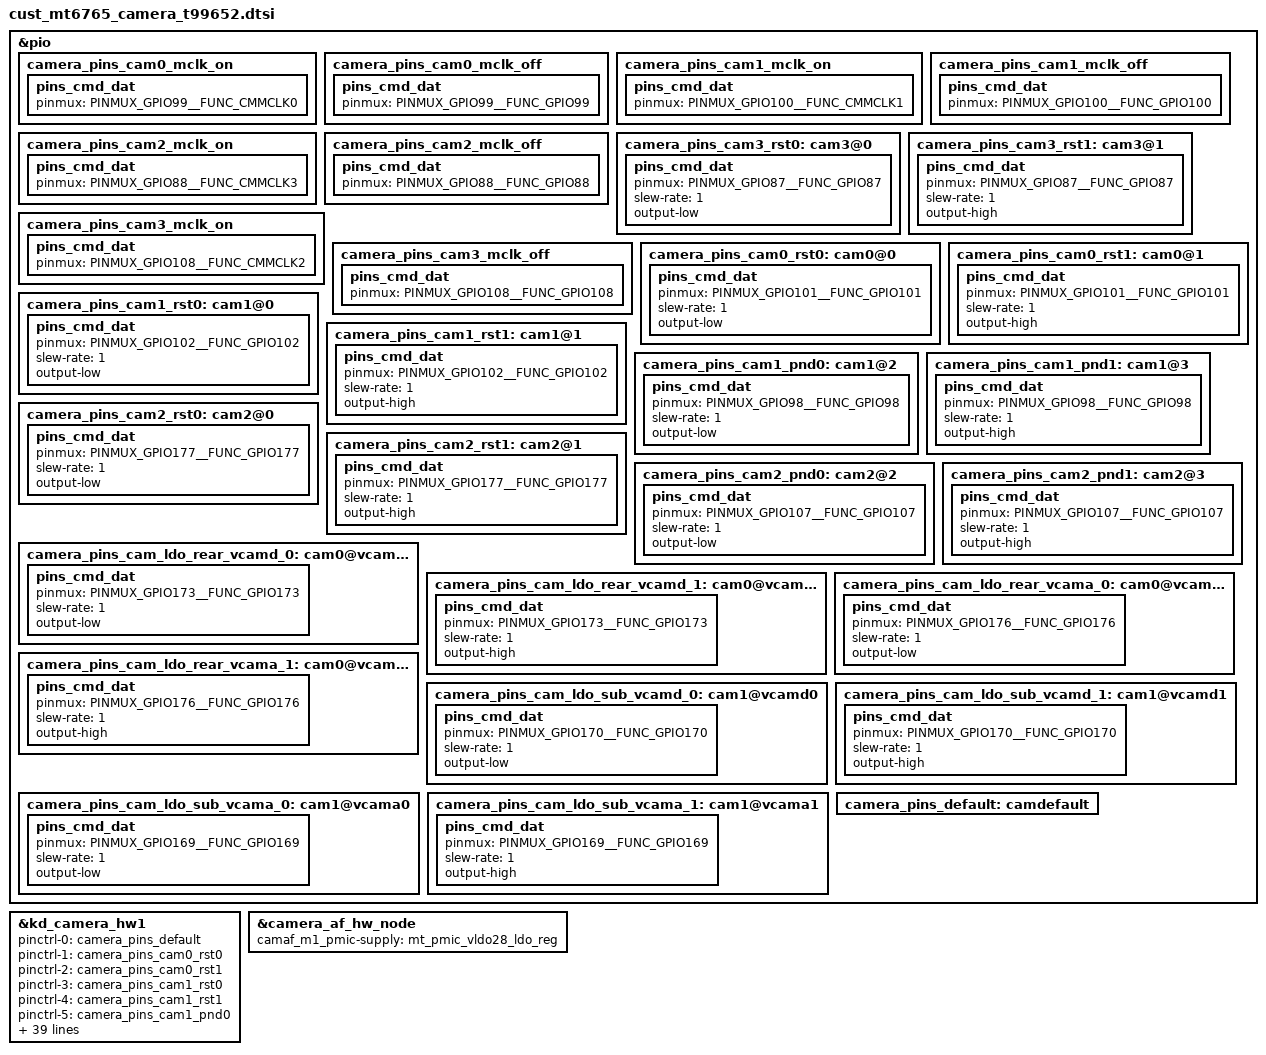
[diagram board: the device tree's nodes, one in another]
// SPDX-License-Identifier: GPL-2.0+
/*
 * Copyright (c) 2019 MediaTek Inc.
 *
 */

/* CAMERA GPIO standardization */
&pio {
	camera_pins_cam0_mclk_on: camera_pins_cam0_mclk_on {
		pins_cmd_dat {
			pinmux = <PINMUX_GPIO99__FUNC_CMMCLK0>;
		};
	};
	camera_pins_cam0_mclk_off: camera_pins_cam0_mclk_off {
		pins_cmd_dat {
			pinmux = <PINMUX_GPIO99__FUNC_GPIO99>;
		};
	};
	camera_pins_cam1_mclk_on: camera_pins_cam1_mclk_on {
		pins_cmd_dat {
			pinmux = <PINMUX_GPIO100__FUNC_CMMCLK1>;
		};
	};
	camera_pins_cam1_mclk_off: camera_pins_cam1_mclk_off {
		pins_cmd_dat {
			pinmux = <PINMUX_GPIO100__FUNC_GPIO100>;
		};
	};
	camera_pins_cam2_mclk_on: camera_pins_cam2_mclk_on {
		pins_cmd_dat {
			pinmux = <PINMUX_GPIO88__FUNC_CMMCLK3>;
		};
	};
	camera_pins_cam2_mclk_off: camera_pins_cam2_mclk_off {
		pins_cmd_dat {
			pinmux = <PINMUX_GPIO88__FUNC_GPIO88>;
		};
	};
    /*+bug584789,liuxingyu.wt,MODIFY,2020/10/13,rogue hi556 gc02m1 sensor bringup*/
	camera_pins_cam3_rst0: cam3@0 {
		pins_cmd_dat {
			pinmux = <PINMUX_GPIO87__FUNC_GPIO87>;
			slew-rate = <1>;
			output-low;
		};
	};
	camera_pins_cam3_rst1: cam3@1 {
		pins_cmd_dat {
			pinmux = <PINMUX_GPIO87__FUNC_GPIO87>;
			slew-rate = <1>;
			output-high;
		};
	};
/*+bug595172,zhanghengyuan.wt,DELETE,2020/10/19,camera gpio160 customization*/
/*
	camera_pins_cam3_pnd0: cam3@2 {
		pins_cmd_dat {
			pinmux = <PINMUX_GPIO160__FUNC_GPIO160>;
			slew-rate = <1>;
			output-low;
		};
	};
	camera_pins_cam3_pnd1: cam3@3 {
		pins_cmd_dat {
			pinmux = <PINMUX_GPIO160__FUNC_GPIO160>;
			slew-rate = <1>;
			output-high;
		};
	};
*/
/*-bug595172,zhanghengyuan.wt,DELETE,2020/10/19,camera gpio160 customization*/
	camera_pins_cam3_mclk_on: camera_pins_cam3_mclk_on {
		pins_cmd_dat {
			pinmux = <PINMUX_GPIO108__FUNC_CMMCLK2>;
		};
	};
	camera_pins_cam3_mclk_off: camera_pins_cam3_mclk_off {
		pins_cmd_dat {
			pinmux = <PINMUX_GPIO108__FUNC_GPIO108>;
		};
	};
    /*-bug584789,liuxingyu.wt,MODIFY,2020/10/13,rogue hi556 gc02m1 sensor bringup*/
	camera_pins_cam0_rst0: cam0@0 {
		pins_cmd_dat {
			pinmux = <PINMUX_GPIO101__FUNC_GPIO101>;
			slew-rate = <1>;
			output-low;
		};
	};
	camera_pins_cam0_rst1: cam0@1 {
		pins_cmd_dat {
			pinmux = <PINMUX_GPIO101__FUNC_GPIO101>;
			slew-rate = <1>;
			output-high;
		};
	};
//+bug584789,chenbocheng.wt,REMOVE,2020/10/31,the gpio97 pin is the charge enalbe pin
/*
	camera_pins_cam0_pnd0: cam0@2 {
		pins_cmd_dat {
			pinmux = <PINMUX_GPIO97__FUNC_GPIO97>;
			slew-rate = <1>;
			output-low;
		};
	};
	camera_pins_cam0_pnd1: cam0@3 {
		pins_cmd_dat {
			pinmux = <PINMUX_GPIO97__FUNC_GPIO97>;
			slew-rate = <1>;
			output-high;
		};
	};
*/
//-bug584789,chenbocheng.wt,REMOVE,2020/10/31,the gpio97 pin is the charge enalbe pin
	camera_pins_cam1_rst0: cam1@0 {
		pins_cmd_dat {
			pinmux = <PINMUX_GPIO102__FUNC_GPIO102>;
			slew-rate = <1>;
			output-low;
		};
	};
	camera_pins_cam1_rst1: cam1@1 {
		pins_cmd_dat {
			pinmux = <PINMUX_GPIO102__FUNC_GPIO102>;
			slew-rate = <1>;
			output-high;
		};
	};
	camera_pins_cam1_pnd0: cam1@2 {
		pins_cmd_dat {
			pinmux = <PINMUX_GPIO98__FUNC_GPIO98>;
			slew-rate = <1>;
			output-low;
		};
	};
	camera_pins_cam1_pnd1: cam1@3 {
		pins_cmd_dat {
			pinmux = <PINMUX_GPIO98__FUNC_GPIO98>;
			slew-rate = <1>;
			output-high;
		};
	};
	camera_pins_cam2_rst0: cam2@0 {
		pins_cmd_dat {
			pinmux = <PINMUX_GPIO177__FUNC_GPIO177>;
			slew-rate = <1>;
			output-low;
		};
	};
	camera_pins_cam2_rst1: cam2@1 {
		pins_cmd_dat {
			pinmux = <PINMUX_GPIO177__FUNC_GPIO177>;
			slew-rate = <1>;
			output-high;
		};
	};
/*bug584789,zhanghengyuan.wt,MODIFY,2020/10/14,rogue gc02m1b sensor bringup*/
	camera_pins_cam2_pnd0: cam2@2 {
		pins_cmd_dat {
			pinmux = <PINMUX_GPIO107__FUNC_GPIO107>;
			slew-rate = <1>;
			output-low;
		};
	};
	camera_pins_cam2_pnd1: cam2@3 {
		pins_cmd_dat {
			pinmux = <PINMUX_GPIO107__FUNC_GPIO107>;
			slew-rate = <1>;
			output-high;
		};
	};
/*bug584789,zhanghengyuan.wt,MODIFY,2020/10/14,rogue gc02m1b sensor bringup*/
        /*+bug584789,zhouyikuan.wt,MODIFY,2020/10/12,rogue_dongci_s5k3l6 sensor bringup*/
	camera_pins_cam_ldo_rear_vcamd_0: cam0@vcamd0 {
		pins_cmd_dat {
			pinmux = <PINMUX_GPIO173__FUNC_GPIO173>;
			slew-rate = <1>;
			output-low;
		};
	};
	camera_pins_cam_ldo_rear_vcamd_1: cam0@vcamd1 {
		pins_cmd_dat {
			pinmux = <PINMUX_GPIO173__FUNC_GPIO173>;
			slew-rate = <1>;
			output-high;
		};
	};
    camera_pins_cam_ldo_rear_vcama_0: cam0@vcama0 {
            pins_cmd_dat {
                    pinmux = <PINMUX_GPIO176__FUNC_GPIO176>;
                    slew-rate = <1>;
                    output-low;
            };
    };
    camera_pins_cam_ldo_rear_vcama_1: cam0@vcama1 {
            pins_cmd_dat {
                    pinmux = <PINMUX_GPIO176__FUNC_GPIO176>;
                    slew-rate = <1>;
                    output-high;
            };
    };
    /*-bug584789,zhouyikuan.wt,MODIFY,2020/10/12,rogue_dongci_s5k3l6 sensor bringup*/
	camera_pins_cam_ldo_sub_vcamd_0: cam1@vcamd0 {
		pins_cmd_dat {
			pinmux = <PINMUX_GPIO170__FUNC_GPIO170>;
			slew-rate = <1>;
			output-low;
		};
	};
	camera_pins_cam_ldo_sub_vcamd_1: cam1@vcamd1 {
		pins_cmd_dat {
			pinmux = <PINMUX_GPIO170__FUNC_GPIO170>;
			slew-rate = <1>;
			output-high;
		};
	};
	camera_pins_cam_ldo_sub_vcama_0: cam1@vcama0 {
		pins_cmd_dat {
			pinmux = <PINMUX_GPIO169__FUNC_GPIO169>;
			slew-rate = <1>;
			output-low;
		};
	};
	camera_pins_cam_ldo_sub_vcama_1: cam1@vcama1 {
		pins_cmd_dat {
			pinmux = <PINMUX_GPIO169__FUNC_GPIO169>;
			slew-rate = <1>;
			output-high;
		};
	};
	camera_pins_default: camdefault {
	};

};

&kd_camera_hw1 {
	pinctrl-names = "default",
			"cam0_rst0",
			"cam0_rst1",
			//"cam0_pnd0",
			//"cam0_pnd1",
			"cam1_rst0",
			"cam1_rst1",
			"cam1_pnd0",
			"cam1_pnd1",
			"cam2_rst0",
			"cam2_rst1",
			"cam2_pnd0",
			"cam2_pnd1",
			"cam0_vcamd_on",
			"cam0_vcamd_off",
            /*+bug584789,zhouyikuan.wt,MODIFY,2020/10/12,rogue_dongci_s5k3l6 sensor bringup*/
            "cam0_vcama_on",
            "cam0_vcama_off",
            /*-bug584789,zhouyikuan.wt,MODIFY,2020/10/12,rogue_dongci_s5k3l6 sensor bringup*/
			"cam1_vcamd_on",
			"cam1_vcamd_off",
			"cam1_vcama_on",
			"cam1_vcama_off",
			"cam0_mclk_on",
			"cam0_mclk_off",
			"cam1_mclk_on",
			"cam1_mclk_off",
			"cam2_mclk_on",
			"cam2_mclk_off",
			"cam3_rst0",
			"cam3_rst1",
			"cam3_mclk_on",
			"cam3_mclk_off";

	pinctrl-0 = <&camera_pins_default>;
	pinctrl-1 = <&camera_pins_cam0_rst0>;
	pinctrl-2 = <&camera_pins_cam0_rst1>;
	//pinctrl-3 = <&camera_pins_cam0_pnd0>;
	//pinctrl-4 = <&camera_pins_cam0_pnd1>;
	pinctrl-3 = <&camera_pins_cam1_rst0>;
	pinctrl-4 = <&camera_pins_cam1_rst1>;
	pinctrl-5 = <&camera_pins_cam1_pnd0>;
	pinctrl-6 = <&camera_pins_cam1_pnd1>;
	pinctrl-7 = <&camera_pins_cam2_rst0>;
	pinctrl-8 = <&camera_pins_cam2_rst1>;
	pinctrl-9 = <&camera_pins_cam2_pnd0>;
	pinctrl-10 = <&camera_pins_cam2_pnd1>;
	pinctrl-11 = <&camera_pins_cam_ldo_rear_vcamd_1>;
	pinctrl-12 = <&camera_pins_cam_ldo_rear_vcamd_0>;
    /*+bug584789,zhouyikuan.wt,MODIFY,2020/10/12,rogue_dongci_s5k3l6 sensor bringup*/
    pinctrl-13 = <&camera_pins_cam_ldo_rear_vcama_1>;
    pinctrl-14 = <&camera_pins_cam_ldo_rear_vcama_0>;
    /*-bug584789,zhouyikuan.wt,MODIFY,2020/10/12,rogue_dongci_s5k3l6 sensor bringup*/
	pinctrl-15 = <&camera_pins_cam_ldo_sub_vcamd_1>;
	pinctrl-16 = <&camera_pins_cam_ldo_sub_vcamd_0>;
	pinctrl-17 = <&camera_pins_cam_ldo_sub_vcama_1>;
	pinctrl-18 = <&camera_pins_cam_ldo_sub_vcama_0>;
	pinctrl-19 = <&camera_pins_cam0_mclk_on>;
	pinctrl-20 = <&camera_pins_cam0_mclk_off>;
	pinctrl-21 = <&camera_pins_cam1_mclk_on>;
	pinctrl-22 = <&camera_pins_cam1_mclk_off>;
	pinctrl-23 = <&camera_pins_cam2_mclk_on>;
	pinctrl-24 = <&camera_pins_cam2_mclk_off>;
	pinctrl-25 = <&camera_pins_cam3_rst0>;
	pinctrl-26 = <&camera_pins_cam3_rst1>;
	pinctrl-27 = <&camera_pins_cam3_mclk_on>;
	pinctrl-38 = <&camera_pins_cam3_mclk_off>;

    /*+bug584789,zhouyikuan.wt,MODIFY,2020/10/12,rogue_dongci_s5k3l6 sensor bringup*/
	/*cam0_vcama-supply = <&mt_pmic_vcama_ldo_reg>;*/
    cam0_vcamio-supply = <&mt_pmic_vcamio_ldo_reg>;
    cam1_vcama-supply = <&mt_pmic_vcama_ldo_reg>;
    cam1_vcamd-supply = <&mt_pmic_vcamd_ldo_reg>;
    cam1_vcamio-supply = <&mt_pmic_vcamio_ldo_reg>;
       /*	cam2_vcamd-supply = <&mt_pmic_vcamd_ldo_reg>;*/
	cam2_vcama-supply = <&mt_pmic_vcama_ldo_reg>;
	cam2_vcamio-supply = <&mt_pmic_vcamio_ldo_reg>;
	/*bug596770,liuxiangyin.wt,MODIFY,2020/12/17,turn off rogue gc02m1 sensor DVDD*/
	/*cam3_vcamd-supply = <&mt_pmic_vcamd_ldo_reg>;*/
	cam3_vcamio-supply = <&mt_pmic_vcamio_ldo_reg>;
	cam3_vcama-supply = <&mt_pmic_vcama_ldo_reg>;

	cam0_enable_sensor = "rogue_s5k3l6_rear_dc_mipi_raw rogue_hi1336_rear_txd_mipi_raw";
	cam1_enable_sensor = "rogue_hi846_front_st_mipi_raw rogue_gc8034_front_lh_mipi_raw";
	cam2_enable_sensor = "rogue_gc02m1b_dep_cxt_mipi_raw rogue_bf2253_dep_lh_mipi_raw";
    /*-bug584789,zhouyikuan.wt,MODIFY,2020/10/12,rogue_dongci_s5k3l6 sensor bringup*/
	cam3_enable_sensor = "rogue_gc02m1_micro_lh_mipi_raw rogue_gc02m1_micro_cxt_mipi_raw";

	status = "okay";

};

&camera_af_hw_node {
        /*+bug584789,zhouyikuan.wt,ADD,2020/20/22,CN3927E af bring up*/
        /*camaf_m2_pmic-supply = <&mt_pmic_vmc_ldo_reg>;*/
        camaf_m1_pmic-supply = <&mt_pmic_vldo28_ldo_reg>;
        /*-bug584789,zhouyikuan.wt,ADD,2020/20/22,CN3927E af bring up*/
	status = "okay";
};
/* CAMERA GPIO end */
